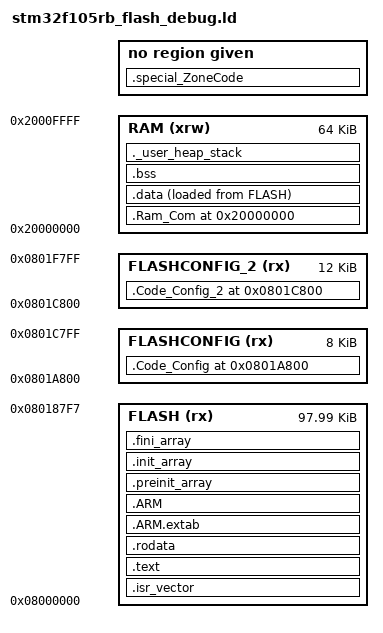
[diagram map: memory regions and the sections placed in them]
/*
******************************************************************************
**
** @file        : LinkerScript.ld
**
** @author      : Auto-generated by STM32CubeIDE
**
** @brief       : Linker script for STM32F105RBTx Device from STM32F1 series
**                      128Kbytes FLASH
**                      64Kbytes RAM
**
**                Set heap size, stack size and stack location according
**                to application requirements.
**
**                Set memory bank area and size if external memory is used
**
**  Target      : STMicroelectronics STM32
**
**  Distribution: The file is distributed as is, without any warranty
**                of any kind.
**
******************************************************************************
** @attention
**
** <h2><center>&copy; Copyright (c) 2021 STMicroelectronics.
** All rights reserved.</center></h2>
**
** This software component is licensed by ST under BSD 3-Clause license,
** the "License"; You may not use this file except in compliance with the
** License. You may obtain a copy of the License at:
**                        opensource.org/licenses/BSD-3-Clause
**
******************************************************************************
*/

/* Entry Point */
ENTRY(Reset_Handler)

/* Highest address of the user mode stack */
_estack = ORIGIN(RAM) + LENGTH(RAM); /* end of "RAM" Ram type memory */

_Min_Heap_Size = 0x200; /* required amount of heap */
_Min_Stack_Size = 0x400; /* required amount of stack */

/* Memories definition */
MEMORY
{
  RAM    (xrw)    : ORIGIN = 0x20000000,   LENGTH = 64K
  FLASH    (rx)    : ORIGIN = 0x8000000,   LENGTH = 98K-8
  FLASHCONFIG (rx) : ORIGIN = 0x0801A800, LENGTH = 8192
  FLASHCONFIG_2 (rx) : ORIGIN = 0x0801C800, LENGTH = 12288
}

/* Sections */
SECTIONS
{
/*-----------------------------------------------------------------------------*/
  .Code_Config 0x0801A800:
  {
	KEEP(*(.Code_Config.APP_TFT_PMV_MODE))
	KEEP(*(.Code_Config.APP_TFT_PMV_MESSAGE))
	KEEP(*(.Code_Config.APP_TFT_PMV_TABLE))
	KEEP(*(.Code_Config.APP_TFT_PMV_NU))
	KEEP(*(.Code_Config.APP_TFT_PMV_I2I))
	KEEP(*(.Code_Config.APP_TFT_PMV_I2V))
  } > FLASHCONFIG

 /*-----------------------------------------------------------------------------*/
  .Code_Config_2 0x0801C800 :
  {
	KEEP(*(.Code_Config_2.APP_TFT_NB_PMV_CARTE_LED))
	. = ALIGN(4);
	KEEP(*(.Code_Config_2.APP_LISTE_FACADE))
	KEEP(*(.Code_Config_2.APP_TFT_TOUCHE))
	KEEP(*(.Code_Config_2.APP_TFT_VOYANT))
	KEEP(*(.Code_Config_2.APP_TFT_PICTO_TOUCHE))
	KEEP(*(.Code_Config_2.APP_CHARGE_CAN))
	KEEP(*(.Code_Config_2.APP_TFT_TOUCHE_G_CAN))
	KEEP(*(.Code_Config_2.APP_TFT_ECRAN_CAN))
	KEEP(*(.Code_Config_2.APP_TFT_LANGUE_CAN))
	KEEP(*(.Code_Config_2.APP_LISTE_BLOC))
	KEEP(*(.Code_Config_2.APP_TFT_TOUCHE_UP_DOWN_CAN))
	KEEP(*(.Code_Config_2.APP_TFT_ECRAN_BAS_CAN))
	KEEP(*(.Code_Config_2.APP_TFT_GESTION_PML))
	KEEP(*(.Code_Config_2.APP_TFT_GESTION_ODOMETRE))
	KEEP(*(.Code_Config_2.APP_TFT_PMV_LANGUE_USED))
	KEEP(*(.Code_Config_2.APP_TFT_MIRROR_SCREEN))
	KEEP(*(.Code_Config_2.APP_PARAMETRE_1))
	KEEP(*(.Code_Config_2.APP_PARAMETRE_2))
	KEEP(*(.Code_Config_2.APP_PARAMETRE_PMV))
	KEEP(*(.Code_Config_2.APP_VERSION_CONFIG))
	KEEP(*(.Code_Config_2.APP_TYPE_INTERFACE_COM))
	KEEP(*(.Code_Config_2.APP_TYPE_GESTION_WIFI_BLT))
	KEEP(*(.Code_Config_2.APP_CFG_NAME))
	KEEP(*(.Code_Config_2.APP_TYPE_CAN_EXTERNE_TAB))
	KEEP(*(.Code_Config_2.APP_UTC_SIGN))
	KEEP(*(.Code_Config_2.APP_UTC_VALUE))
	KEEP(*(.Code_Config_2.APP_GESTION_SUMER_WINTER))
  } > FLASHCONFIG_2
/*-----------------------------------------------------------------------------*/
 .special_ZoneCode :
   {
      KEEP(*(.special_Const_Code))
   }
/*-----------------------------------------------------------------------------*/
  .Ram_Com 0x20000000 :
  {
    KEEP(*(.Ram_Com.P_L_Rpg_boot_reserved))
	KEEP(*(.Ram_Com.P_L_Rpg_boot_demande))
	KEEP(*(.Ram_Com.P_L_Ram_bloc_adr_low))
	KEEP(*(.Ram_Com.APP_Boot_Can_Speed))
	KEEP(*(.Ram_Com.P_L_Ram_bloc_adr_high))
	KEEP(*(.Ram_Com.P_L_Ram_bloc_adr_low2))  
	KEEP(*(.Ram_Com.P_L_Ram_bloc_adr_high2))
  } > RAM

 /*-----------------------------------------------------------------------------*/


  /* The startup code into "FLASH" Rom type memory */
  .isr_vector :
  {
    . = ALIGN(4);
    KEEP(*(.isr_vector)) /* Startup code */
    . = ALIGN(4);
  } >FLASH

  /* The program code and other data into "FLASH" Rom type memory */
  .text :
  {
    . = ALIGN(4);
    *(.text)           /* .text sections (code) */
    *(.text*)          /* .text* sections (code) */
    *(.glue_7)         /* glue arm to thumb code */
    *(.glue_7t)        /* glue thumb to arm code */
    *(.eh_frame)

    KEEP (*(.init))
    KEEP (*(.fini))

    . = ALIGN(4);
    _etext = .;        /* define a global symbols at end of code */
  } >FLASH

  /* Constant data into "FLASH" Rom type memory */
  .rodata :
  {
    . = ALIGN(4);
    *(.rodata)         /* .rodata sections (constants, strings, etc.) */
    *(.rodata*)        /* .rodata* sections (constants, strings, etc.) */
    . = ALIGN(4);
  } >FLASH

  .ARM.extab   : {
    . = ALIGN(4);
    *(.ARM.extab* .gnu.linkonce.armextab.*)
    . = ALIGN(4);
  } >FLASH

  .ARM : {
    . = ALIGN(4);
    __exidx_start = .;
    *(.ARM.exidx*)
    __exidx_end = .;
    . = ALIGN(4);
  } >FLASH

  .preinit_array     :
  {
    . = ALIGN(4);
    PROVIDE_HIDDEN (__preinit_array_start = .);
    KEEP (*(.preinit_array*))
    PROVIDE_HIDDEN (__preinit_array_end = .);
    . = ALIGN(4);
  } >FLASH

  .init_array :
  {
    . = ALIGN(4);
    PROVIDE_HIDDEN (__init_array_start = .);
    KEEP (*(SORT(.init_array.*)))
    KEEP (*(.init_array*))
    PROVIDE_HIDDEN (__init_array_end = .);
    . = ALIGN(4);
  } >FLASH

  .fini_array :
  {
    . = ALIGN(4);
    PROVIDE_HIDDEN (__fini_array_start = .);
    KEEP (*(SORT(.fini_array.*)))
    KEEP (*(.fini_array*))
    PROVIDE_HIDDEN (__fini_array_end = .);
    . = ALIGN(4);
  } >FLASH

  /* Used by the startup to initialize data */
  _sidata = LOADADDR(.data);

  /* Initialized data sections into "RAM" Ram type memory */
  .data :
  {
    . = ALIGN(4);
    _sdata = .;        /* create a global symbol at data start */
    *(.data)           /* .data sections */
    *(.data*)          /* .data* sections */
    *(.RamFunc)        /* .RamFunc sections */
    *(.RamFunc*)       /* .RamFunc* sections */

    . = ALIGN(4);
    _edata = .;        /* define a global symbol at data end */

  } >RAM AT> FLASH

  /* Uninitialized data section into "RAM" Ram type memory */
  . = ALIGN(4);
  .bss :
  {
    /* This is used by the startup in order to initialize the .bss section */
    _sbss = .;         /* define a global symbol at bss start */
    __bss_start__ = _sbss;
    *(.bss)
    *(.bss*)
    *(COMMON)

    . = ALIGN(4);
    _ebss = .;         /* define a global symbol at bss end */
    __bss_end__ = _ebss;
  } >RAM

  /* User_heap_stack section, used to check that there is enough "RAM" Ram  type memory left */
  ._user_heap_stack :
  {
    . = ALIGN(8);
    PROVIDE ( end = . );
    PROVIDE ( _end = . );
    . = . + _Min_Heap_Size;
    . = . + _Min_Stack_Size;
    . = ALIGN(8);
  } >RAM

  /* Remove information from the compiler libraries */
  /DISCARD/ :
  {
    libc.a ( * )
    libm.a ( * )
    libgcc.a ( * )
  }

  .ARM.attributes 0 : { *(.ARM.attributes) }
}
